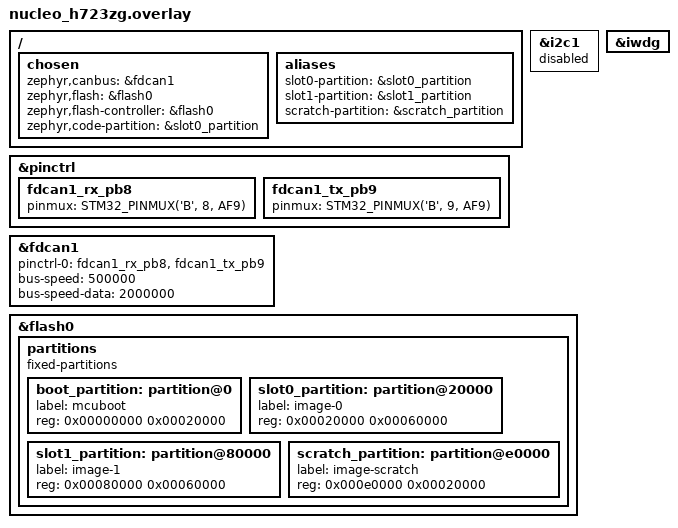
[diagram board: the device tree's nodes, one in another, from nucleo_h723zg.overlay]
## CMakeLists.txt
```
cmake_minimum_required(VERSION 3.20.0)

find_package(Zephyr REQUIRED HINTS $ENV{ZEPHYR_BASE})

project(ids_node)

test_sysbuild()

target_sources(app PRIVATE
    src/main.c 
    src/manual_inference.c
)
```

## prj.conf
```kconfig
CONFIG_PICOLIBC=n
CONFIG_NEWLIB_LIBC=y


CONFIG_GPIO=y
CONFIG_CAN=y
CONFIG_CAN_FD_MODE=y
CONFIG_LOG=y
CONFIG_WATCHDOG=y
CONFIG_WDT_DISABLE_AT_BOOT=y
CONFIG_FPU=y
```

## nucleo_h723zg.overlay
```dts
&pinctrl {
    fdcan1_rx_pb8: fdcan1_rx_pb8 {
        pinmux = <STM32_PINMUX('B', 8, AF9)>;
    };
    fdcan1_tx_pb9: fdcan1_tx_pb9 {
        pinmux = <STM32_PINMUX('B', 9, AF9)>;
    };
};

&i2c1 {
    status = "disabled";
};

&fdcan1 {
    pinctrl-0 = <&fdcan1_rx_pb8 &fdcan1_tx_pb9>;
    pinctrl-names = "default";
    status = "okay";
    bus-speed = <500000>;
    bus-speed-data = <2000000>;
};
&iwdg {
    status = "okay";
};

/ {
    chosen {
        zephyr,canbus = &fdcan1;
        zephyr,flash = &flash0;
        zephyr,flash-controller = &flash0;
        zephyr,code-partition = &slot0_partition; 

    };

    aliases {
        slot0-partition = &slot0_partition;
        slot1-partition = &slot1_partition;
        scratch-partition = &scratch_partition;
    };
};

&flash0 {

    status = "okay";

    partitions {
        compatible = "fixed-partitions";
        #address-cells = <1>;
        #size-cells = <1>;

        boot_partition: partition@0 {
            label = "mcuboot";
            reg = <0x00000000 0x00020000>;
        };

        slot0_partition: partition@20000 {
            label = "image-0";
            reg = <0x00020000 0x00060000>;
        };

        slot1_partition: partition@80000 {
            label = "image-1";
            reg = <0x00080000 0x00060000>;
        };

        scratch_partition: partition@e0000 {
            label = "image-scratch";
            reg = <0x000e0000 0x00020000>;
        };
    };
};
```

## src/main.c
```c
#include <zephyr/kernel.h>
#include <zephyr/drivers/can.h>
#include <zephyr/logging/log.h>
#include <zephyr/drivers/watchdog.h>
#include <zephyr/drivers/gpio.h>
#include "model_weights.h"
#include "manual_inference.h"


LOG_MODULE_REGISTER(ids_node, LOG_LEVEL_INF);

const struct device *can_dev = DEVICE_DT_GET(DT_CHOSEN(zephyr_canbus));
const struct device *wdt = DEVICE_DT_GET(DT_NODELABEL(iwdg));
static const struct gpio_dt_spec button = GPIO_DT_SPEC_GET(DT_ALIAS(sw0),gpios);

K_MSGQ_DEFINE(can_rx_queue, sizeof(struct can_frame), 10, 4);

void can_callback(const struct device *dev, struct can_frame *frame, void *user_data)
{ 
  k_msgq_put(&can_rx_queue, frame, K_NO_WAIT);
}


int main(void)
{ 
  int err;
  int wdt_channel_id;  
  //Device check
    if(!device_is_ready(can_dev)){
  LOG_ERR("CAN device not ready");
  return -1;
}
  //watchdog check
  if(!device_is_ready(wdt)){
    LOG_ERR("watchdog device is not ready");
    return -1;
  }
  //button check
  if(!gpio_is_ready_dt(&button)){
    LOG_ERR("button device not ready");
    return -1;
  }
  //watchdog setup min_window = 0ms, max_Window = 2000ms
  struct wdt_timeout_cfg wdt_config = {
      .window.min = 0,
      .window.max = 2000,
      .callback = NULL,
      .flags = WDT_FLAG_RESET_SOC
  };

  wdt_channel_id = wdt_install_timeout(wdt, &wdt_config);
  if(wdt_channel_id < 0){
    LOG_ERR("watchdog install failed: %d", wdt_channel_id);
    return 0;

  }
  //button setup
  gpio_pin_configure_dt(&button, GPIO_INPUT);
  err = wdt_setup(wdt,0);
  if (err < 0) {
    LOG_ERR("watchdog setup failed: %d", err);
    return 0;
  }
  LOG_INF("CAN device ready: %s", can_dev->name);
    
    //starting the can 
    can_start(can_dev);
    
    struct can_filter filter = {
      .flags = CAN_FILTER_IDE ,
      .id = 0,
      .mask = 0
    };
    
    can_add_rx_filter(can_dev, &can_callback, NULL, &filter);

    struct can_filter std_filter = {
        .flags = 0, // Standard 11-bit
        .id = 0,
        .mask = 0
    };
    can_add_rx_filter(can_dev, &can_callback, NULL, &std_filter);
    
    LOG_INF("ids_node (H723ZG) listening on CAN-FD...");

    // --- Start-> Manual UDS request sending setup --- //
    struct can_frame diag_req = {0};
    diag_req.flags = 0;
    diag_req.id = 0x7DF;
    diag_req.dlc = 8;
    diag_req.data[0] = 0x02;
    diag_req.data[1] = 0x10;
    diag_req.data[2] = 0x01;
    
    int64_t last_send_time = 0;
    struct can_frame rx_frame;

    while(1) {

      while (k_msgq_get(&can_rx_queue, &rx_frame, K_NO_WAIT)==0){
        if(rx_frame.id == 0x7E8){
          LOG_INF("UDS RESPONSE : %02X %02X %02X", rx_frame.data[0], rx_frame.data[1], rx_frame.data[2]);
        }
        else  if(rx_frame.id == 0x18F00400){ // specific check, engine mcu to avoid false negative

            float score = anomaly_score(rx_frame.data);

            if(score > ANOMALY_THRESHOLD){
                LOG_ERR("Intrusion Detected: Score: %d/1000", (int)(score*1000));
            }
            else {
                LOG_INF("Rx ID: 0x%08X Data: [%02X %02X %02X %02X %02X %02X %02X %02X]",
                    rx_frame.id,
                    rx_frame.data[0], rx_frame.data[1], rx_frame.data[2], rx_frame.data[3],
                    rx_frame.data[4], rx_frame.data[5], rx_frame.data[6], rx_frame.data[7]);
            }
          
        }
        else {
            //
        }
      }
      
      
      if(gpio_pin_get_dt(&button) != 1){
        wdt_feed(wdt,wdt_channel_id);
      }
      else {
        LOG_WRN("FAULT INJECTED: Body freeze simulated, not feeding watchdog");
      }
      LOG_INF("Body ECU running...  (Press button to simulate failure)");

      int64_t now = k_uptime_get();

      if((now - last_send_time) >= 5000){

        LOG_INF("Time Reached: Sending UDS Request...");
        int ret = can_send(can_dev, &diag_req, K_NO_WAIT, NULL,NULL);
        if(ret ==0){
          LOG_INF("UDS Request Sent Successfully");
        }
        else {
          LOG_ERR("Filed to send UDS Request: %d", ret);
        }
        last_send_time = now;

      }
      k_sleep(K_MSEC(100));
    }

    
    return 0;
    
}
```

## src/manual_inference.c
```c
#include <math.h>
#include <zephyr/types.h>
#include "manual_inference.h"
#include "model_weights.h"

// RelU Activation 
static float relu(float x){
    return x > 0 ? x : 0;
}

// sigmoid activation
static float sigmoid(float x) {
    return 1.0f/(1.0f + expf(-x));
}

float anomaly_score(uint8_t *data){


    //input normalization
    float input[8];
    for(int i = 0; i < 8; i++){
        input[i] = (float) data[i]/255.0f;

    }

    //encoder : putting the 8 bits into the 4 bits
    float  hidden[4];
    for(int h = 0; h<4; h++){
        hidden[h] = layer_0_b[h];
        for(int i=0; i<8; i++){
            hidden[h] += input[i] * layer_0_w[(i*4)+h];
        }
        hidden[h] = relu(hidden[h]);
    }

    float output[8];
    for (int j = 0; j < 8; j++){
        output[j] = layer_1_b[j];
        for(int h = 0; h < 4; h++){
            output[j] += hidden[h]*layer_1_w[(h*8)+j];
        }
        output[j] = sigmoid(output[j]);
    }

    float total_error = 0.0f;
    for(int i = 0; i < 8; i++){
        total_error += fabsf(input[i] - output[i]);
    }
    float avg_error = total_error/8.0f;
    return avg_error;
}
```

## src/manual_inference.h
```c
#ifndef MANUAL_INFERENCE_H
#define MANUAL_INFERECE_H

float anomaly_score(uint8_t *data);

#endif
```

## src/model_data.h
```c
#ifndef MODEL_DATA_H
#define MODEL_DATA_H
#include <stdlign.h>

const unsigned char g_model[] __attribute__((aligned(16))) = {
0x1c, 0x00, 0x00, 0x00, 0x54, 0x46, 0x4c, 0x33, 0x14, 0x00, 0x20, 0x00, 
0x1c, 0x00, 0x18, 0x00, 0x14, 0x00, 0x10, 0x00, 0x0c, 0x00, 0x00, 0x00, 
0x08, 0x00, 0x04, 0x00, 0x14, 0x00, 0x00, 0x00, 0x1c, 0x00, 0x00, 0x00, 
0x8c, 0x00, 0x00, 0x00, 0xe4, 0x00, 0x00, 0x00, 0x14, 0x03, 0x00, 0x00, 
0x24, 0x03, 0x00, 0x00, 0x74, 0x07, 0x00, 0x00, 0x03, 0x00, 0x00, 0x00, 
0x01, 0x00, 0x00, 0x00, 0x04, 0x00, 0x00, 0x00, 0xa2, 0xfc, 0xff, 0xff, 
0x0c, 0x00, 0x00, 0x00, 0x1c, 0x00, 0x00, 0x00, 0x3c, 0x00, 0x00, 0x00, 
0x0f, 0x00, 0x00, 0x00, 0x73, 0x65, 0x72, 0x76, 0x69, 0x6e, 0x67, 0x5f, 
0x64, 0x65, 0x66, 0x61, 0x75, 0x6c, 0x74, 0x00, 0x01, 0x00, 0x00, 0x00, 
0x04, 0x00, 0x00, 0x00, 0x90, 0xff, 0xff, 0xff, 0x07, 0x00, 0x00, 0x00, 
0x04, 0x00, 0x00, 0x00, 0x08, 0x00, 0x00, 0x00, 0x6f, 0x75, 0x74, 0x70, 
0x75, 0x74, 0x5f, 0x30, 0x00, 0x00, 0x00, 0x00, 0x01, 0x00, 0x00, 0x00, 
0x04, 0x00, 0x00, 0x00, 0xee, 0xfd, 0xff, 0xff, 0x04, 0x00, 0x00, 0x00, 
0x0f, 0x00, 0x00, 0x00, 0x6b, 0x65, 0x72, 0x61, 0x73, 0x5f, 0x74, 0x65, 
0x6e, 0x73, 0x6f, 0x72, 0x5f, 0x32, 0x34, 0x00, 0x02, 0x00, 0x00, 0x00, 
0x34, 0x00, 0x00, 0x00, 0x04, 0x00, 0x00, 0x00, 0xdc, 0xff, 0xff, 0xff, 
0x0a, 0x00, 0x00, 0x00, 0x04, 0x00, 0x00, 0x00, 0x13, 0x00, 0x00, 0x00, 
0x43, 0x4f, 0x4e, 0x56, 0x45, 0x52, 0x53, 0x49, 0x4f, 0x4e, 0x5f, 0x4d, 
0x45, 0x54, 0x41, 0x44, 0x41, 0x54, 0x41, 0x00, 0x08, 0x00, 0x0c, 0x00, 
0x08, 0x00, 0x04, 0x00, 0x08, 0x00, 0x00, 0x00, 0x09, 0x00, 0x00, 0x00, 
0x04, 0x00, 0x00, 0x00, 0x13, 0x00, 0x00, 0x00, 0x6d, 0x69, 0x6e, 0x5f, 
0x72, 0x75, 0x6e, 0x74, 0x69, 0x6d, 0x65, 0x5f, 0x76, 0x65, 0x72, 0x73, 
0x69, 0x6f, 0x6e, 0x00, 0x0b, 0x00, 0x00, 0x00, 0x2c, 0x02, 0x00, 0x00, 
0x24, 0x02, 0x00, 0x00, 0x94, 0x01, 0x00, 0x00, 0x5c, 0x01, 0x00, 0x00, 
0x3c, 0x01, 0x00, 0x00, 0xac, 0x00, 0x00, 0x00, 0xa4, 0x00, 0x00, 0x00, 
0x9c, 0x00, 0x00, 0x00, 0x94, 0x00, 0x00, 0x00, 0x74, 0x00, 0x00, 0x00, 
0x04, 0x00, 0x00, 0x00, 0x96, 0xfe, 0xff, 0xff, 0x04, 0x00, 0x00, 0x00, 
0x60, 0x00, 0x00, 0x00, 0x10, 0x00, 0x00, 0x00, 0x00, 0x00, 0x00, 0x00, 
0x08, 0x00, 0x0e, 0x00, 0x08, 0x00, 0x04, 0x00, 0x08, 0x00, 0x00, 0x00, 
0x10, 0x00, 0x00, 0x00, 0x24, 0x00, 0x00, 0x00, 0x00, 0x00, 0x06, 0x00, 
0x08, 0x00, 0x04, 0x00, 0x06, 0x00, 0x00, 0x00, 0x04, 0x00, 0x00, 0x00, 
0x00, 0x00, 0x00, 0x00, 0x0c, 0x00, 0x18, 0x00, 0x14, 0x00, 0x10, 0x00, 
0x0c, 0x00, 0x04, 0x00, 0x0c, 0x00, 0x00, 0x00, 0xb8, 0x0e, 0xd7, 0x3f, 
0x0a, 0xc8, 0x8c, 0x4d, 0x02, 0x00, 0x00, 0x00, 0x02, 0x00, 0x00, 0x00, 
0x04, 0x00, 0x00, 0x00, 0x06, 0x00, 0x00, 0x00, 0x32, 0x2e, 0x31, 0x39, 
0x2e, 0x30, 0x00, 0x00, 0x02, 0xff, 0xff, 0xff, 0x04, 0x00, 0x00, 0x00, 
0x10, 0x00, 0x00, 0x00, 0x31, 0x2e, 0x31, 0x34, 0x2e, 0x30, 0x00, 0x00, 
0x00, 0x00, 0x00, 0x00, 0x00, 0x00, 0x00, 0x00, 0x58, 0xfa, 0xff, 0xff, 
0x5c, 0xfa, 0xff, 0xff, 0x60, 0xfa, 0xff, 0xff, 0x2a, 0xff, 0xff, 0xff, 
0x04, 0x00, 0x00, 0x00, 0x80, 0x00, 0x00, 0x00, 0x75, 0xc8, 0x9f, 0xbd, 
0xe1, 0x56, 0xc0, 0x3e, 0xb1, 0x1b, 0xab, 0x3d, 0xc0, 0x44, 0xcd, 0xbe, 
0x17, 0x10, 0x50, 0x3c, 0xc4, 0xb1, 0x31, 0x3e, 0x90, 0x91, 0x0b, 0xbf, 
0xa1, 0x95, 0x2d, 0xbf, 0x53, 0xf8, 0x0c, 0xc0, 0x4c, 0xdd, 0x9d, 0xbf, 
0x11, 0x8f, 0xda, 0xbf, 0x94, 0x26, 0x25, 0x40, 0x5d, 0x81, 0x4a, 0x40, 
0xb7, 0x34, 0x04, 0xbf, 0xf7, 0xd9, 0x09, 0xbf, 0x80, 0xd8, 0x65, 0x3d, 
0x40, 0x3a, 0xe7, 0xbc, 0xa1, 0xef, 0x5c, 0x3e, 0x8f, 0xf9, 0xaf, 0xbe, 
0x90, 0xd6, 0x1c, 0xbf, 0xd0, 0xf3, 0x2d, 0xbe, 0x6d, 0x2c, 0xd9, 0xbe, 
0x38, 0x63, 0x15, 0xbf, 0xd9, 0x3e, 0x1b, 0xbf, 0x77, 0x70, 0x39, 0x3f, 
0x84, 0x94, 0x89, 0x3f, 0x77, 0x4c, 0x16, 0x3f, 0x46, 0xb0, 0x1a, 0x40, 
0x12, 0x2c, 0x44, 0xbf, 0x63, 0x4b, 0x0d, 0x3f, 0xf3, 0xe5, 0x0d, 0x3f, 
0x76, 0x8b, 0xd4, 0x3e, 0xb6, 0xff, 0xff, 0xff, 0x04, 0x00, 0x00, 0x00, 
0x10, 0x00, 0x00, 0x00, 0x60, 0x2f, 0xf1, 0xbd, 0x61, 0xcd, 0x3b, 0x3f, 
0xba, 0x9a, 0x97, 0xbd, 0xd7, 0x95, 0x9a, 0x3f, 0xd2, 0xff, 0xff, 0xff, 
0x04, 0x00, 0x00, 0x00, 0x20, 0x00, 0x00, 0x00, 0x9d, 0xe1, 0x3f, 0xbf, 
0x8f, 0xf6, 0x46, 0xbf, 0x5d, 0xec, 0x5f, 0xbf, 0x91, 0x33, 0x4d, 0xc0, 
0x46, 0x95, 0xd5, 0xbf, 0xcd, 0xe6, 0x5b, 0xbf, 0x90, 0x0f, 0x76, 0xbf, 
0x7c, 0x05, 0x83, 0xbf, 0x00, 0x00, 0x06, 0x00, 0x08, 0x00, 0x04, 0x00, 
0x06, 0x00, 0x00, 0x00, 0x04, 0x00, 0x00, 0x00, 0x80, 0x00, 0x00, 0x00, 
0xa9, 0x93, 0x80, 0xbe, 0x67, 0x78, 0xfc, 0xbf, 0x17, 0xec, 0x5b, 0x3d, 
0xf8, 0xf6, 0xf0, 0xbf, 0x5b, 0xbc, 0xbe, 0x3e, 0xf7, 0xd9, 0x0f, 0xc0, 
0x6b, 0x9a, 0xc4, 0xbd, 0xcd, 0xf8, 0xa1, 0xbf, 0x2c, 0x8b, 0x74, 0x3e, 
0x66, 0x3d, 0xff, 0xbf, 0x03, 0x37, 0x0f, 0x3f, 0xd5, 0x61, 0xca, 0xbf, 
0x15, 0x75, 0xb2, 0x3e, 0xfa, 0x0f, 0xba, 0x3e, 0x05, 0xaf, 0xcd, 0x3e, 
0x7f, 0x01, 0x7e, 0x3f, 0xb3, 0xa7, 0xef, 0xbe, 0x06, 0x2c, 0xa0, 0x3f, 
0xf5, 0xc6, 0x26, 0x3f, 0xf9, 0x25, 0xae, 0xbf, 0x5c, 0x59, 0xe2, 0xbe, 
0x22, 0x4f, 0xb8, 0xbf, 0xa3, 0xfb, 0xa7, 0x3e, 0x16, 0xd1, 0x0e, 0xc0, 
0xe6, 0x22, 0x60, 0x3e, 0x5c, 0x70, 0xe7, 0xbf, 0x58, 0xae, 0x10, 0x3e, 
0x5c, 0x45, 0xca, 0xbf, 0x9c, 0xf9, 0xf6, 0x3e, 0x91, 0x33, 0xe1, 0xbf, 
0xa6, 0x35, 0xf9, 0xbe, 0xa1, 0xce, 0xbf, 0xbf, 0xcc, 0xfb, 0xff, 0xff, 
0xd0, 0xfb, 0xff, 0xff, 0x0f, 0x00, 0x00, 0x00, 0x4d, 0x4c, 0x49, 0x52, 
0x20, 0x43, 0x6f, 0x6e, 0x76, 0x65, 0x72, 0x74, 0x65, 0x64, 0x2e, 0x00, 
0x01, 0x00, 0x00, 0x00, 0x14, 0x00, 0x00, 0x00, 0x00, 0x00, 0x0e, 0x00, 
0x18, 0x00, 0x14, 0x00, 0x10, 0x00, 0x0c, 0x00, 0x08, 0x00, 0x04, 0x00, 
0x0e, 0x00, 0x00, 0x00, 0x14, 0x00, 0x00, 0x00, 0x1c, 0x00, 0x00, 0x00, 
0xd0, 0x00, 0x00, 0x00, 0xd4, 0x00, 0x00, 0x00, 0xd8, 0x00, 0x00, 0x00, 
0x04, 0x00, 0x00, 0x00, 0x6d, 0x61, 0x69, 0x6e, 0x00, 0x00, 0x00, 0x00, 
0x03, 0x00, 0x00, 0x00, 0x78, 0x00, 0x00, 0x00, 0x34, 0x00, 0x00, 0x00, 
0x10, 0x00, 0x00, 0x00, 0x00, 0x00, 0x0a, 0x00, 0x10, 0x00, 0x0c, 0x00, 
0x08, 0x00, 0x04, 0x00, 0x0a, 0x00, 0x00, 0x00, 0x0c, 0x00, 0x00, 0x00, 
0x10, 0x00, 0x00, 0x00, 0x01, 0x00, 0x00, 0x00, 0x01, 0x00, 0x00, 0x00, 
0x07, 0x00, 0x00, 0x00, 0x01, 0x00, 0x00, 0x00, 0x06, 0x00, 0x00, 0x00, 
0xce, 0xff, 0xff, 0xff, 0x10, 0x00, 0x00, 0x00, 0x00, 0x00, 0x00, 0x08, 
0x0c, 0x00, 0x00, 0x00, 0x10, 0x00, 0x00, 0x00, 0x74, 0xfc, 0xff, 0xff, 
0x01, 0x00, 0x00, 0x00, 0x06, 0x00, 0x00, 0x00, 0x03, 0x00, 0x00, 0x00, 
0x05, 0x00, 0x00, 0x00, 0x01, 0x00, 0x00, 0x00, 0x02, 0x00, 0x00, 0x00, 
0x00, 0x00, 0x0e, 0x00, 0x16, 0x00, 0x00, 0x00, 0x10, 0x00, 0x0c, 0x00, 
0x0b, 0x00, 0x04, 0x00, 0x0e, 0x00, 0x00, 0x00, 0x18, 0x00, 0x00, 0x00, 
0x00, 0x00, 0x00, 0x08, 0x18, 0x00, 0x00, 0x00, 0x1c, 0x00, 0x00, 0x00, 
0x00, 0x00, 0x06, 0x00, 0x08, 0x00, 0x07, 0x00, 0x06, 0x00, 0x00, 0x00, 
0x00, 0x00, 0x00, 0x01, 0x01, 0x00, 0x00, 0x00, 0x05, 0x00, 0x00, 0x00, 
0x03, 0x00, 0x00, 0x00, 0x00, 0x00, 0x00, 0x00, 0x04, 0x00, 0x00, 0x00, 
0x03, 0x00, 0x00, 0x00, 0x01, 0x00, 0x00, 0x00, 0x07, 0x00, 0x00, 0x00, 
0x01, 0x00, 0x00, 0x00, 0x00, 0x00, 0x00, 0x00, 0x08, 0x00, 0x00, 0x00, 
0xe8, 0x02, 0x00, 0x00, 0x90, 0x02, 0x00, 0x00, 0x3c, 0x02, 0x00, 0x00, 
0xdc, 0x01, 0x00, 0x00, 0x88, 0x01, 0x00, 0x00, 0xe4, 0x00, 0x00, 0x00, 
0x60, 0x00, 0x00, 0x00, 0x04, 0x00, 0x00, 0x00, 0x4e, 0xfd, 0xff, 0xff, 
0x00, 0x00, 0x00, 0x01, 0x14, 0x00, 0x00, 0x00, 0x1c, 0x00, 0x00, 0x00, 
0x1c, 0x00, 0x00, 0x00, 0x08, 0x00, 0x00, 0x00, 0x34, 0x00, 0x00, 0x00, 
0x02, 0x00, 0x00, 0x00, 0xff, 0xff, 0xff, 0xff, 0x08, 0x00, 0x00, 0x00, 
0x38, 0xfd, 0xff, 0xff, 0x1b, 0x00, 0x00, 0x00, 0x53, 0x74, 0x61, 0x74, 
0x65, 0x66, 0x75, 0x6c, 0x50, 0x61, 0x72, 0x74, 0x69, 0x74, 0x69, 0x6f, 
0x6e, 0x65, 0x64, 0x43, 0x61, 0x6c, 0x6c, 0x5f, 0x31, 0x3a, 0x30, 0x00, 
0x02, 0x00, 0x00, 0x00, 0x01, 0x00, 0x00, 0x00, 0x08, 0x00, 0x00, 0x00, 
0xa6, 0xfd, 0xff, 0xff, 0x00, 0x00, 0x00, 0x01, 0x14, 0x00, 0x00, 0x00, 
0x1c, 0x00, 0x00, 0x00, 0x1c, 0x00, 0x00, 0x00, 0x07, 0x00, 0x00, 0x00, 
0x5c, 0x00, 0x00, 0x00, 0x02, 0x00, 0x00, 0x00, 0xff, 0xff, 0xff, 0xff, 
0x08, 0x00, 0x00, 0x00, 0x90, 0xfd, 0xff, 0xff, 0x42, 0x00, 0x00, 0x00, 
0x73, 0x65, 0x71, 0x75, 0x65, 0x6e, 0x74, 0x69, 0x61, 0x6c, 0x5f, 0x36, 
0x5f, 0x31, 0x2f, 0x64, 0x65, 0x6e, 0x73, 0x65, 0x5f, 0x31, 0x33, 0x5f, 
0x31, 0x2f, 0x4d, 0x61, 0x74, 0x4d, 0x75, 0x6c, 0x3b, 0x73, 0x65, 0x71, 
0x75, 0x65, 0x6e, 0x74, 0x69, 0x61, 0x6c, 0x5f, 0x36, 0x5f, 0x31, 0x2f, 
0x64, 0x65, 0x6e, 0x73, 0x65, 0x5f, 0x31, 0x33, 0x5f, 0x31, 0x2f, 0x42, 
0x69, 0x61, 0x73, 0x41, 0x64, 0x64, 0x00, 0x00, 0x02, 0x00, 0x00, 0x00, 
0x01, 0x00, 0x00, 0x00, 0x08, 0x00, 0x00, 0x00, 0x26, 0xfe, 0xff, 0xff, 
0x00, 0x00, 0x00, 0x01, 0x14, 0x00, 0x00, 0x00, 0x1c, 0x00, 0x00, 0x00, 
0x1c, 0x00, 0x00, 0x00, 0x06, 0x00, 0x00, 0x00, 0x7c, 0x00, 0x00, 0x00, 
0x02, 0x00, 0x00, 0x00, 0xff, 0xff, 0xff, 0xff, 0x04, 0x00, 0x00, 0x00, 
0x10, 0xfe, 0xff, 0xff, 0x61, 0x00, 0x00, 0x00, 0x73, 0x65, 0x71, 0x75, 
0x65, 0x6e, 0x74, 0x69, 0x61, 0x6c, 0x5f, 0x36, 0x5f, 0x31, 0x2f, 0x64, 
0x65, 0x6e, 0x73, 0x65, 0x5f, 0x31, 0x32, 0x5f, 0x31, 0x2f, 0x4d, 0x61, 
0x74, 0x4d, 0x75, 0x6c, 0x3b, 0x73, 0x65, 0x71, 0x75, 0x65, 0x6e, 0x74, 
0x69, 0x61, 0x6c, 0x5f, 0x36, 0x5f, 0x31, 0x2f, 0x64, 0x65, 0x6e, 0x73, 
0x65, 0x5f, 0x31, 0x32, 0x5f, 0x31, 0x2f, 0x52, 0x65, 0x6c, 0x75, 0x3b, 
0x73, 0x65, 0x71, 0x75, 0x65, 0x6e, 0x74, 0x69, 0x61, 0x6c, 0x5f, 0x36, 
0x5f, 0x31, 0x2f, 0x64, 0x65, 0x6e, 0x73, 0x65, 0x5f, 0x31, 0x32, 0x5f, 
0x31, 0x2f, 0x42, 0x69, 0x61, 0x73, 0x41, 0x64, 0x64, 0x00, 0x00, 0x00, 
0x02, 0x00, 0x00, 0x00, 0x01, 0x00, 0x00, 0x00, 0x04, 0x00, 0x00, 0x00, 
0x1a, 0xff, 0xff, 0xff, 0x00, 0x00, 0x00, 0x01, 0x10, 0x00, 0x00, 0x00, 
0x10, 0x00, 0x00, 0x00, 0x05, 0x00, 0x00, 0x00, 0x30, 0x00, 0x00, 0x00, 
0xa0, 0xfe, 0xff, 0xff, 0x20, 0x00, 0x00, 0x00, 0x73, 0x65, 0x71, 0x75, 
0x65, 0x6e, 0x74, 0x69, 0x61, 0x6c, 0x5f, 0x36, 0x5f, 0x31, 0x2f, 0x64, 
0x65, 0x6e, 0x73, 0x65, 0x5f, 0x31, 0x32, 0x5f, 0x31, 0x2f, 0x4d, 0x61, 
0x74, 0x4d, 0x75, 0x6c, 0x00, 0x00, 0x00, 0x00, 0x02, 0x00, 0x00, 0x00, 
0x04, 0x00, 0x00, 0x00, 0x08, 0x00, 0x00, 0x00, 0x6a, 0xff, 0xff, 0xff, 
0x00, 0x00, 0x00, 0x01, 0x10, 0x00, 0x00, 0x00, 0x10, 0x00, 0x00, 0x00, 
0x04, 0x00, 0x00, 0x00, 0x40, 0x00, 0x00, 0x00, 0xf0, 0xfe, 0xff, 0xff, 
0x30, 0x00, 0x00, 0x00, 0x73, 0x65, 0x71, 0x75, 0x65, 0x6e, 0x74, 0x69, 
0x61, 0x6c, 0x5f, 0x36, 0x5f, 0x31, 0x2f, 0x64, 0x65, 0x6e, 0x73, 0x65, 
0x5f, 0x31, 0x32, 0x5f, 0x31, 0x2f, 0x42, 0x69, 0x61, 0x73, 0x41, 0x64, 
0x64, 0x2f, 0x52, 0x65, 0x61, 0x64, 0x56, 0x61, 0x72, 0x69, 0x61, 0x62, 
0x6c, 0x65, 0x4f, 0x70, 0x00, 0x00, 0x00, 0x00, 0x01, 0x00, 0x00, 0x00, 
0x04, 0x00, 0x00, 0x00, 0xc6, 0xff, 0xff, 0xff, 0x00, 0x00, 0x00, 0x01, 
0x10, 0x00, 0x00, 0x00, 0x10, 0x00, 0x00, 0x00, 0x03, 0x00, 0x00, 0x00, 
0x1c, 0x00, 0x00, 0x00, 0x4c, 0xff, 0xff, 0xff, 0x0f, 0x00, 0x00, 0x00, 
0x61, 0x72, 0x69, 0x74, 0x68, 0x2e, 0x63, 0x6f, 0x6e, 0x73, 0x74, 0x61, 
0x6e, 0x74, 0x31, 0x00, 0x01, 0x00, 0x00, 0x00, 0x08, 0x00, 0x00, 0x00, 
0x00, 0x00, 0x16, 0x00, 0x18, 0x00, 0x14, 0x00, 0x00, 0x00, 0x10, 0x00, 
0x0c, 0x00, 0x08, 0x00, 0x00, 0x00, 0x00, 0x00, 0x00, 0x00, 0x07, 0x00, 
0x16, 0x00, 0x00, 0x00, 0x00, 0x00, 0x00, 0x01, 0x10, 0x00, 0x00, 0x00, 
0x10, 0x00, 0x00, 0x00, 0x02, 0x00, 0x00, 0x00, 0x1c, 0x00, 0x00, 0x00, 
0x9c, 0xff, 0xff, 0xff, 0x0e, 0x00, 0x00, 0x00, 0x61, 0x72, 0x69, 0x74, 
0x68, 0x2e, 0x63, 0x6f, 0x6e, 0x73, 0x74, 0x61, 0x6e, 0x74, 0x00, 0x00, 
0x02, 0x00, 0x00, 0x00, 0x08, 0x00, 0x00, 0x00, 0x04, 0x00, 0x00, 0x00, 
0x00, 0x00, 0x16, 0x00, 0x1c, 0x00, 0x18, 0x00, 0x00, 0x00, 0x14, 0x00, 
0x10, 0x00, 0x0c, 0x00, 0x00, 0x00, 0x00, 0x00, 0x08, 0x00, 0x07, 0x00, 
0x16, 0x00, 0x00, 0x00, 0x00, 0x00, 0x00, 0x01, 0x14, 0x00, 0x00, 0x00, 
0x20, 0x00, 0x00, 0x00, 0x20, 0x00, 0x00, 0x00, 0x01, 0x00, 0x00, 0x00, 
0x40, 0x00, 0x00, 0x00, 0x02, 0x00, 0x00, 0x00, 0xff, 0xff, 0xff, 0xff, 
0x08, 0x00, 0x00, 0x00, 0x04, 0x00, 0x04, 0x00, 0x04, 0x00, 0x00, 0x00, 
0x21, 0x00, 0x00, 0x00, 0x73, 0x65, 0x72, 0x76, 0x69, 0x6e, 0x67, 0x5f, 
0x64, 0x65, 0x66, 0x61, 0x75, 0x6c, 0x74, 0x5f, 0x6b, 0x65, 0x72, 0x61, 
0x73, 0x5f, 0x74, 0x65, 0x6e, 0x73, 0x6f, 0x72, 0x5f, 0x32, 0x34, 0x3a, 
0x30, 0x00, 0x00, 0x00, 0x02, 0x00, 0x00, 0x00, 0x01, 0x00, 0x00, 0x00, 
0x08, 0x00, 0x00, 0x00, 0x02, 0x00, 0x00, 0x00, 0x20, 0x00, 0x00, 0x00, 
0x04, 0x00, 0x00, 0x00, 0xf4, 0xff, 0xff, 0xff, 0x0e, 0x00, 0x00, 0x00, 
0x00, 0x00, 0x00, 0x0e, 0x0c, 0x00, 0x0c, 0x00, 0x0b, 0x00, 0x00, 0x00, 
0x00, 0x00, 0x04, 0x00, 0x0c, 0x00, 0x00, 0x00, 0x09, 0x00, 0x00, 0x00, 
0x00, 0x00, 0x00, 0x09, 
};

const int g_model_len = 2008;
#endif
```

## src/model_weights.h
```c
#ifndef MODEL_WEIGHTS_H
#define MODEL_WEIGHTS_H
//layer0Weights
static const float layer_0_w[] = {-0.14457147f, -1.1587931f, 1.1027217f, 0.6002047f, 0.031120073f, -1.5389549f, 0.5535054f, 0.7931251f, 0.6367637f, -1.1350454f, 0.91531086f, 0.19434085f, -0.290526f, 2.4916391f, 2.382493f, 0.9054307f, 0.2135238f, 2.0804062f, -0.12978368f, 1.9995536f, -0.09098762f, 0.58068067f, 0.54955107f, 0.6075706f, -0.375346f, -0.6335755f, 0.1437521f, -0.24024463f, -0.5756022f, -0.068127155f, -0.5302513f, 0.23001105f, };
//layer0Biases
static const float layer_0_b[] = {-0.10706852f, 0.89881516f, 0.58431613f, 1.5121917f, };
//layer1Weights
static const float layer_1_w[] = {0.25889248f, 0.1874749f, 0.60050136f, -0.05472249f, -0.11957944f, 0.32414424f, 0.4187058f, 0.011807544f, -1.7962976f, -1.4310087f, -1.2867742f, 0.4866211f, 0.58114535f, -1.5324521f, -1.7295218f, -1.6874784f, -0.9863841f, -0.9446789f, -1.3462416f, 1.6842169f, -0.8890952f, -0.6753871f, -1.3619616f, -1.6708158f, -1.5442076f, -1.0918647f, -1.4680779f, -0.5908915f, 0.4520274f, -1.8590872f, -1.7047797f, -1.0476409f, };
//layer1Biases
static const float layer_1_b[] = {-0.61519766f, -0.9745239f, -0.81601214f, -2.7941413f, -2.0981019f, -0.6851642f, -0.5465359f, -0.7918763f, };

#define ANOMALY_THRESHOLD 0.05f // it's more than 3*sd, but since the environment is controlled. we can use it.

#endif
```
